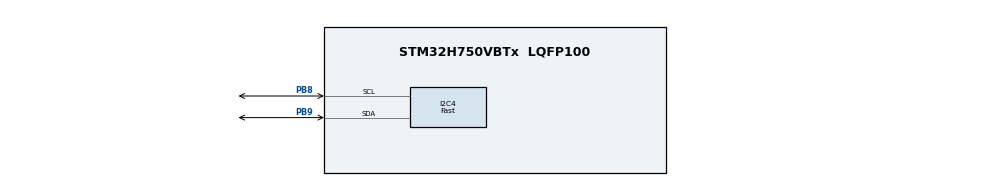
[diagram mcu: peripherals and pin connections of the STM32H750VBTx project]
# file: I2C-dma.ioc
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Bdma.I2C4_TX.0.Direction=DMA_MEMORY_TO_PERIPH
Bdma.I2C4_TX.0.EventEnable=DISABLE
Bdma.I2C4_TX.0.Instance=BDMA_Channel7
Bdma.I2C4_TX.0.MemDataAlignment=DMA_MDATAALIGN_BYTE
Bdma.I2C4_TX.0.MemInc=DMA_MINC_ENABLE
Bdma.I2C4_TX.0.Mode=DMA_NORMAL
Bdma.I2C4_TX.0.PeriphDataAlignment=DMA_PDATAALIGN_BYTE
Bdma.I2C4_TX.0.PeriphInc=DMA_PINC_DISABLE
Bdma.I2C4_TX.0.Polarity=HAL_DMAMUX_REQ_GEN_RISING
Bdma.I2C4_TX.0.Priority=DMA_PRIORITY_HIGH
Bdma.I2C4_TX.0.RequestNumber=1
Bdma.I2C4_TX.0.SignalID=NONE
Bdma.I2C4_TX.0.SyncEnable=DISABLE
Bdma.I2C4_TX.0.SyncPolarity=HAL_DMAMUX_SYNC_NO_EVENT
Bdma.I2C4_TX.0.SyncRequestNumber=1
Bdma.I2C4_TX.0.SyncSignalID=NONE
Bdma.Request0=I2C4_TX
Bdma.RequestsNb=1
I2C4.I2C_Speed_Mode=I2C_Fast
I2C4.Timing=0x009034B6
Mcu.Family=STM32H7
Mcu.Name=STM32H750VBTx
Mcu.Package=LQFP100
NVIC.BDMA_Channel7_IRQn=true\:0\:0\:false\:false\:true\:false\:true\:true
NVIC.I2C4_ER_IRQn=true\:0\:0\:false\:false\:true\:true\:true\:true
NVIC.I2C4_EV_IRQn=true\:0\:0\:false\:false\:true\:true\:true\:true
NVIC.PriorityGroup=NVIC_PRIORITYGROUP_4
NVIC.TIM2_IRQn=true\:0\:0\:false\:false\:true\:true\:true\:true
PB8.Mode=I2C
PB8.Signal=I2C4_SCL
PB9.Mode=I2C
PB9.Signal=I2C4_SDA
ProjectManager.HeapSize=0x200
ProjectManager.StackSize=0x400
ProjectManager.TargetToolchain=MDK-ARM V5.32
RCC.ADCFreq_Value=129000000
RCC.APB1Freq_Value=100000000
RCC.APB2Freq_Value=100000000
RCC.APB3Freq_Value=100000000
RCC.APB4Freq_Value=100000000
RCC.CortexFreq_Value=400000000
RCC.D1PPRE=RCC_APB3_DIV2
RCC.D2PPRE1=RCC_APB1_DIV2
RCC.D2PPRE2=RCC_APB2_DIV2
RCC.D3PPRE=RCC_APB4_DIV2
RCC.DIVM1=4
RCC.DIVN1=50
RCC.HCLKFreq_Value=200000000
RCC.HPRE=RCC_HCLK_DIV2
RCC.PLL2FRACN=0
RCC.PLL3FRACN=0
RCC.PLLFRACN=0
RCC.SYSCLKFreq_VALUE=400000000
RCC.SYSCLKSource=RCC_SYSCLKSOURCE_PLLCLK
RCC.USBFreq_Value=400000000
TIM2.Period=200-1
TIM2.Prescaler=400-1
VP_TIM2_VS_ClockSourceINT.Mode=Internal
board=custom

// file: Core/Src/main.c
/* USER CODE BEGIN Header */
/**
  ******************************************************************************
  * @file           : main.c
  * @brief          : Main program body
  ******************************************************************************
  * @attention
  *
  * Copyright (c) 2025 STMicroelectronics.
  * All rights reserved.
  *
  * This software is licensed under terms that can be found in the LICENSE file
  * in the root directory of this software component.
  * If no LICENSE file comes with this software, it is provided AS-IS.
  *
  ******************************************************************************
  */
/* USER CODE END Header */
#include "main.h"
#include "bdma.h"
#include "i2c.h"
#include "tim.h"
#include "gpio.h"

/* USER CODE BEGIN Includes */
#include "dac_controller.h"
#include "waveform_generator.h"
/* USER CODE END Includes */

/* USER CODE BEGIN PV */
extern uint8_t transfer_complete;
extern DMA_HandleTypeDef hdma_i2c4_tx;
/* USER CODE END PV */

void SystemClock_Config(void);

int main(void)
{

  /* MCU Configuration--------------------------------------------------------*/

  /* Reset of all peripherals, Initializes the Flash interface and the Systick. */
  HAL_Init();

  /* Configure the system clock */
  SystemClock_Config();

  /* Initialize all configured peripherals */
  MX_GPIO_Init();
  MX_BDMA_Init();
  MX_I2C4_Init();
  MX_TIM2_Init();

  /* Infinite loop */
  /* USER CODE BEGIN WHILE */
	HAL_StatusTypeDef status;
			uint8_t data[3];
  uint16_t dac_value0 = 2047;  // 12-bit value (0-4095)
//	data[0]=0x40;
  data[0] = (dac_value0 >> 4); // Upper 4 bits
  data[1] = (dac_value0&0xF)<<4;         // Lower 8 bits
//		SCB_CleanDCache_by_Addr((uint32_t*)data, sizeof(data));
	//	HAL_I2C_Mem_Write_IT(&hi2c4, 0xC0, 0x40, I2C_MEMADD_SIZE_8BIT, data, 2);
//		HAL_I2C_Mem_Write(&hi2c4, 0x60<<1, 0x40, I2C_MEMADD_SIZE_8BIT, data, 2,HAL_MAX_DELAY);
while (hi2c4.State != HAL_I2C_STATE_READY){};
		status=HAL_I2C_Mem_Write_DMA(&hi2c4, 0x60<<1, 0x40, I2C_MEMADD_SIZE_8BIT, data, 2);
	while (HAL_I2C_GetState(&hi2c4) != HAL_I2C_STATE_READY){};
//    dac_controller_init();
//    set_waveform_parameters(WAVE_SINE, 50, 2000);
//    update_timer_frequency(50);
//		HAL_TIM_Base_Start_IT(&htim2);

  while (1)
  {
    /* USER CODE END WHILE */

    /* USER CODE BEGIN 3 */
//		HAL_Delay(5000);
//		static uint8_t wave_type = 0;
//		wave_type = (wave_type + 1) % 3;
//		set_waveform_parameters(wave_type, 20, 2000);  // 20Hz
//		update_timer_frequency(20);
  }
  /* USER CODE END 3 */
}

void SystemClock_Config(void)
{
  RCC_OscInitTypeDef RCC_OscInitStruct = {0};
  RCC_ClkInitTypeDef RCC_ClkInitStruct = {0};

  /** Supply configuration update enable
  */
  HAL_PWREx_ConfigSupply(PWR_LDO_SUPPLY);

  /** Configure the main internal regulator output voltage
  */
  __HAL_PWR_VOLTAGESCALING_CONFIG(PWR_REGULATOR_VOLTAGE_SCALE1);

  while(!__HAL_PWR_GET_FLAG(PWR_FLAG_VOSRDY)) {}

  /** Initializes the RCC Oscillators according to the specified parameters
  * in the RCC_OscInitTypeDef structure.
  */
  RCC_OscInitStruct.OscillatorType = RCC_OSCILLATORTYPE_HSI;
  RCC_OscInitStruct.HSIState = RCC_HSI_DIV1;
  RCC_OscInitStruct.HSICalibrationValue = RCC_HSICALIBRATION_DEFAULT;
  RCC_OscInitStruct.PLL.PLLState = RCC_PLL_ON;
  RCC_OscInitStruct.PLL.PLLSource = RCC_PLLSOURCE_HSI;
  RCC_OscInitStruct.PLL.PLLM = 4;
  RCC_OscInitStruct.PLL.PLLN = 50;
  RCC_OscInitStruct.PLL.PLLP = 2;
  RCC_OscInitStruct.PLL.PLLQ = 2;
  RCC_OscInitStruct.PLL.PLLR = 2;
  RCC_OscInitStruct.PLL.PLLRGE = RCC_PLL1VCIRANGE_3;
  RCC_OscInitStruct.PLL.PLLVCOSEL = RCC_PLL1VCOWIDE;
  RCC_OscInitStruct.PLL.PLLFRACN = 0;
  if (HAL_RCC_OscConfig(&RCC_OscInitStruct) != HAL_OK)
  {
    Error_Handler();
  }

  /** Initializes the CPU, AHB and APB buses clocks
  */
  RCC_ClkInitStruct.ClockType = RCC_CLOCKTYPE_HCLK|RCC_CLOCKTYPE_SYSCLK
                              |RCC_CLOCKTYPE_PCLK1|RCC_CLOCKTYPE_PCLK2
                              |RCC_CLOCKTYPE_D3PCLK1|RCC_CLOCKTYPE_D1PCLK1;
  RCC_ClkInitStruct.SYSCLKSource = RCC_SYSCLKSOURCE_PLLCLK;
  RCC_ClkInitStruct.SYSCLKDivider = RCC_SYSCLK_DIV1;
  RCC_ClkInitStruct.AHBCLKDivider = RCC_HCLK_DIV2;
  RCC_ClkInitStruct.APB3CLKDivider = RCC_APB3_DIV2;
  RCC_ClkInitStruct.APB1CLKDivider = RCC_APB1_DIV2;
  RCC_ClkInitStruct.APB2CLKDivider = RCC_APB2_DIV2;
  RCC_ClkInitStruct.APB4CLKDivider = RCC_APB4_DIV2;

  if (HAL_RCC_ClockConfig(&RCC_ClkInitStruct, FLASH_LATENCY_2) != HAL_OK)
  {
    Error_Handler();
  }
}

/* USER CODE BEGIN 4 */
int error=0;

/* USER CODE END 4 */

void Error_Handler(void)
{
  /* USER CODE BEGIN Error_Handler_Debug */
  /* User can add his own implementation to report the HAL error return state */
  __disable_irq();
	error=1;
  while (1)
  {
  }
  /* USER CODE END Error_Handler_Debug */
}
